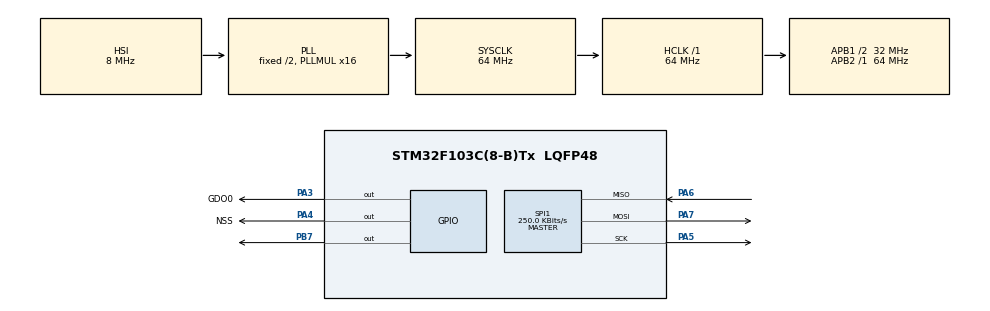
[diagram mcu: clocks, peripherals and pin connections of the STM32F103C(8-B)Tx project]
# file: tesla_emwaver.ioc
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Mcu.Family=STM32F1
Mcu.Name=STM32F103C(8-B)Tx
Mcu.Package=LQFP48
NVIC.PriorityGroup=NVIC_PRIORITYGROUP_4
PA13.Mode=Serial_Wire
PA13.Signal=SYS_JTMS-SWDIO
PA14.Mode=Serial_Wire
PA14.Signal=SYS_JTCK-SWCLK
PA3.GPIO_Label=GDO0
PA3.Signal=GPIO_Output
PA4.GPIO_Label=NSS
PA4.Signal=GPIO_Output
PA5.Mode=Full_Duplex_Master
PA5.Signal=SPI1_SCK
PA6.Mode=Full_Duplex_Master
PA6.Signal=SPI1_MISO
PA7.Mode=Full_Duplex_Master
PA7.Signal=SPI1_MOSI
PB7.Signal=GPIO_Output
ProjectManager.HeapSize=0x200
ProjectManager.StackSize=0x400
ProjectManager.TargetToolchain=STM32CubeIDE
RCC.AHBFreq_Value=64000000
RCC.APB1CLKDivider=RCC_HCLK_DIV2
RCC.APB1Freq_Value=32000000
RCC.APB1TimFreq_Value=64000000
RCC.APB2Freq_Value=64000000
RCC.APB2TimFreq_Value=64000000
RCC.HCLKFreq_Value=64000000
RCC.PLLMUL=RCC_PLL_MUL16
RCC.SYSCLKFreq_VALUE=64000000
RCC.SYSCLKSource=RCC_SYSCLKSOURCE_PLLCLK
RCC.USBFreq_Value=64000000
SPI1.BaudRatePrescaler=SPI_BAUDRATEPRESCALER_256
SPI1.CalculateBaudRate=250.0 KBits/s
SPI1.Direction=SPI_DIRECTION_2LINES
SPI1.Mode=SPI_MODE_MASTER
SPI1.VirtualType=VM_MASTER
board=custom

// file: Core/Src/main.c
/* USER CODE BEGIN Header */
/**
  ******************************************************************************
  * @file           : main.c
  * @brief          : Main program body
  ******************************************************************************
  * @attention
  *
  * Copyright (c) 2023 STMicroelectronics.
  * All rights reserved.
  *
  * This software is licensed under terms that can be found in the LICENSE file
  * in the root directory of this software component.
  * If no LICENSE file comes with this software, it is provided AS-IS.
  *
  ******************************************************************************
  */
/* USER CODE END Header */
#include "main.h"

/* USER CODE BEGIN Includes */
#include "stdio.h"
#include "cc1101.h"

/* USER CODE END Includes */

/* USER CODE BEGIN PD */

#define   WRITE_BURST       0x40
/* USER CODE END PD */

SPI_HandleTypeDef hspi1;

void SystemClock_Config(void);
static void MX_GPIO_Init(void);
static void MX_SPI1_Init(void);

int main(void)
{

  /* MCU Configuration--------------------------------------------------------*/

  /* Reset of all peripherals, Initializes the Flash interface and the Systick. */
  HAL_Init();

  /* Configure the system clock */
  SystemClock_Config();

  /* Initialize all configured peripherals */
  MX_GPIO_Init();
  MX_SPI1_Init();
  /* USER CODE BEGIN 2 */

  Init();              // must be set to initialize the cc1101!
      //CC1101LPL.setCCMode(0);       // set config for internal transmission mode. (1)
  setModulation(2);  // set modulation mode. 0 = 2-FSK, 1 = GFSK, 2 = ASK/OOK, 3 = 4-FSK, 4 = MSK.
  setMHZ(433.92);   // Here you can set your basic frequency. The lib calculates the frequency automatically (default = 433.92).The cc1101 can: 300-348 MHZ, 387-464MHZ and 779-928MHZ. Read More info from datasheet.
  setSyncMode(0);  // Combined sync-word qualifier mode. 0 = No preamble/sync. 1 = 16 sync word bits detected. 2 = 16/16 sync word bits detected. 3 = 30/32 sync word bits detected. 4 = No preamble/sync, carrier-sense above threshold. 5 = 15/16 + carrier-sense above threshold. 6 = 16/16 + carrier-sense above threshold. 7 = 30/32 + carrier-sense above threshold.
   // cclpl.setPA(10);      // set TxPower. The following settings are possible depending on the frequency band.  (-30  -20  -15  -10  -6    0    5    7    10   11   12) Default is max!
      //cclpl.setCrc(1);     // 1 = CRC calculation in TX and CRC check in RX enabled. 0 = CRC disabled for TX and RX.

  SetTx();

  //printf("Hello world!");
  //setMHZ(433.92);
  //spiWriteReg(CC1101_MDMCFG2, 0x30); //ook
  //setPA(10);
  //spiWriteReg(CC1101_FREND0, 0x11); //pa table select first value
  //spiWriteReg(CC1101_PATABLE, 0x00); //set first value 0
  //spiWriteReg(CC1101_PATABLE+1, 0xC0); //set second value 10 dbm (0xC0)

  //spiStrobe(CC1101_SIDLE);
  //setMHZ(433.92);
  //spiStrobe(CC1101_STX);

  //uint8_t patable[8];
  //spiReadBurstReg(CC1101_PATABLE, patable, 8);

  //uint8_t pa7 = patable[7];
  //uint8_t freq1 = spiReadReg(CC1101_FREQ1);
  //uint8_t freq0 = spiReadReg(CC1101_FREQ0);

  //uint8_t sidle_response = spiWriteRead(CC1101_SIDLE);
  //uint8_t stx_response = spiWriteRead(CC1101_STX);
  /* USER CODE END 2 */

  /* Infinite loop */
  /* USER CODE BEGIN WHILE */
  while (1)
  {
	  HAL_GPIO_WritePin (GPIOA, GDO0_Pin, 1);
	  HAL_GPIO_WritePin (GPIOB, GPIO_PIN_7, 1);
	  HAL_Delay(100);
	  HAL_GPIO_WritePin (GPIOA, GDO0_Pin, 0);
	  HAL_GPIO_WritePin (GPIOB, GPIO_PIN_7, 0);
	  HAL_Delay(100);
    /* USER CODE END WHILE */

  }
}

void SystemClock_Config(void)
{
  RCC_OscInitTypeDef RCC_OscInitStruct = {0};
  RCC_ClkInitTypeDef RCC_ClkInitStruct = {0};

  /** Initializes the RCC Oscillators according to the specified parameters
  * in the RCC_OscInitTypeDef structure.
  */
  RCC_OscInitStruct.OscillatorType = RCC_OSCILLATORTYPE_HSI;
  RCC_OscInitStruct.HSIState = RCC_HSI_ON;
  RCC_OscInitStruct.HSICalibrationValue = RCC_HSICALIBRATION_DEFAULT;
  RCC_OscInitStruct.PLL.PLLState = RCC_PLL_ON;
  RCC_OscInitStruct.PLL.PLLSource = RCC_PLLSOURCE_HSI_DIV2;
  RCC_OscInitStruct.PLL.PLLMUL = RCC_PLL_MUL16;
  if (HAL_RCC_OscConfig(&RCC_OscInitStruct) != HAL_OK)
  {
    Error_Handler();
  }

  /** Initializes the CPU, AHB and APB buses clocks
  */
  RCC_ClkInitStruct.ClockType = RCC_CLOCKTYPE_HCLK|RCC_CLOCKTYPE_SYSCLK
                              |RCC_CLOCKTYPE_PCLK1|RCC_CLOCKTYPE_PCLK2;
  RCC_ClkInitStruct.SYSCLKSource = RCC_SYSCLKSOURCE_PLLCLK;
  RCC_ClkInitStruct.AHBCLKDivider = RCC_SYSCLK_DIV1;
  RCC_ClkInitStruct.APB1CLKDivider = RCC_HCLK_DIV2;
  RCC_ClkInitStruct.APB2CLKDivider = RCC_HCLK_DIV1;

  if (HAL_RCC_ClockConfig(&RCC_ClkInitStruct, FLASH_LATENCY_2) != HAL_OK)
  {
    Error_Handler();
  }
}

static void MX_SPI1_Init(void)
{

  /* SPI1 parameter configuration*/
  hspi1.Instance = SPI1;
  hspi1.Init.Mode = SPI_MODE_MASTER;
  hspi1.Init.Direction = SPI_DIRECTION_2LINES;
  hspi1.Init.DataSize = SPI_DATASIZE_8BIT;
  hspi1.Init.CLKPolarity = SPI_POLARITY_LOW;
  hspi1.Init.CLKPhase = SPI_PHASE_1EDGE;
  hspi1.Init.NSS = SPI_NSS_SOFT;
  hspi1.Init.BaudRatePrescaler = SPI_BAUDRATEPRESCALER_256;
  hspi1.Init.FirstBit = SPI_FIRSTBIT_MSB;
  hspi1.Init.TIMode = SPI_TIMODE_DISABLE;
  hspi1.Init.CRCCalculation = SPI_CRCCALCULATION_DISABLE;
  hspi1.Init.CRCPolynomial = 10;
  if (HAL_SPI_Init(&hspi1) != HAL_OK)
  {
    Error_Handler();
  }

}

static void MX_GPIO_Init(void)
{
  GPIO_InitTypeDef GPIO_InitStruct = {0};

  /* GPIO Ports Clock Enable */
  __HAL_RCC_GPIOA_CLK_ENABLE();
  __HAL_RCC_GPIOB_CLK_ENABLE();

  /*Configure GPIO pin Output Level */
  HAL_GPIO_WritePin(GPIOA, GDO0_Pin|NSS_Pin, GPIO_PIN_RESET);

  /*Configure GPIO pin Output Level */
  HAL_GPIO_WritePin(GPIOB, GPIO_PIN_7, GPIO_PIN_SET);

  /*Configure GPIO pins : GDO0_Pin NSS_Pin */
  GPIO_InitStruct.Pin = GDO0_Pin|NSS_Pin;
  GPIO_InitStruct.Mode = GPIO_MODE_OUTPUT_PP;
  GPIO_InitStruct.Pull = GPIO_NOPULL;
  GPIO_InitStruct.Speed = GPIO_SPEED_FREQ_LOW;
  HAL_GPIO_Init(GPIOA, &GPIO_InitStruct);

  /*Configure GPIO pin : PB7 */
  GPIO_InitStruct.Pin = GPIO_PIN_7;
  GPIO_InitStruct.Mode = GPIO_MODE_OUTPUT_PP;
  GPIO_InitStruct.Pull = GPIO_NOPULL;
  GPIO_InitStruct.Speed = GPIO_SPEED_FREQ_LOW;
  HAL_GPIO_Init(GPIOB, &GPIO_InitStruct);

}

/* USER CODE BEGIN 4 */
/*void sendTesla() {

}

void send(uint8_t highlow) {
	if(highlow)

}*/
/* USER CODE END 4 */

void Error_Handler(void)
{
  __disable_irq();
  while (1)
  {
  }
}
